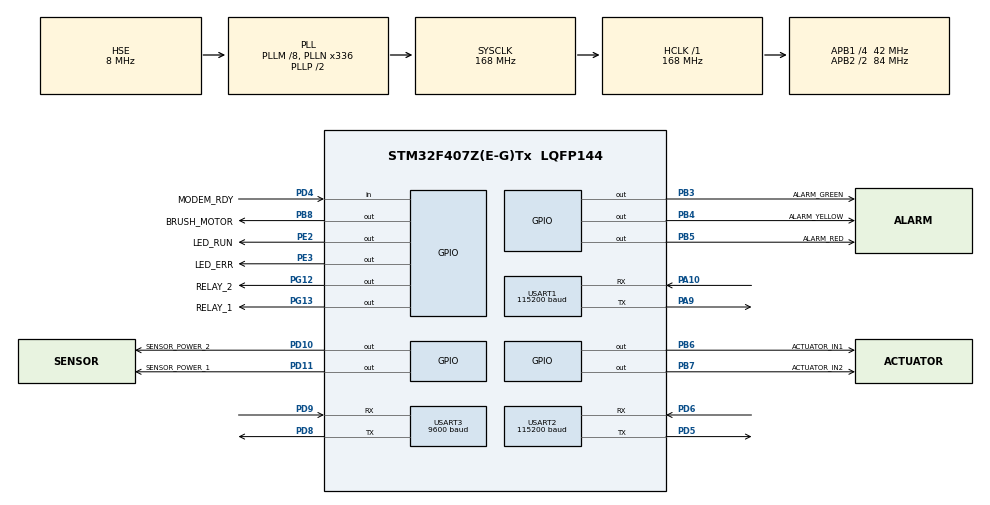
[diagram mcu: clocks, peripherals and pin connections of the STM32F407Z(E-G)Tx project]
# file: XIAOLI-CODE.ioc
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Mcu.Family=STM32F4
Mcu.Name=STM32F407Z(E-G)Tx
Mcu.Package=LQFP144
NVIC.PriorityGroup=NVIC_PRIORITYGROUP_4
NVIC.USART1_IRQn=true\:5\:0\:false\:false\:true\:true\:true
NVIC.USART2_IRQn=true\:5\:0\:false\:false\:true\:true\:true
NVIC.USART3_IRQn=true\:5\:0\:false\:false\:true\:true\:true
PA10.Mode=Asynchronous
PA10.Signal=USART1_RX
PA13.Mode=Serial_Wire
PA13.Signal=SYS_JTMS-SWDIO
PA14.Mode=Serial_Wire
PA14.Signal=SYS_JTCK-SWCLK
PA9.Mode=Asynchronous
PA9.Signal=USART1_TX
PB3.GPIO_Label=ALARM_GREEN
PB3.GPIO_ModeDefaultOutputPP=GPIO_MODE_OUTPUT_PP
PB3.GPIO_PuPd=GPIO_NOPULL
PB3.GPIO_Speed=GPIO_SPEED_FREQ_LOW
PB3.PinState=GPIO_PIN_SET
PB3.Signal=GPIO_Output
PB4.GPIO_Label=ALARM_YELLOW
PB4.GPIO_ModeDefaultOutputPP=GPIO_MODE_OUTPUT_PP
PB4.GPIO_PuPd=GPIO_NOPULL
PB4.GPIO_Speed=GPIO_SPEED_FREQ_LOW
PB4.PinState=GPIO_PIN_SET
PB4.Signal=GPIO_Output
PB5.GPIO_Label=ALARM_RED
PB5.GPIO_ModeDefaultOutputPP=GPIO_MODE_OUTPUT_PP
PB5.GPIO_PuPd=GPIO_NOPULL
PB5.GPIO_Speed=GPIO_SPEED_FREQ_LOW
PB5.PinState=GPIO_PIN_SET
PB5.Signal=GPIO_Output
PB6.GPIO_Label=ACTUATOR_IN1
PB6.GPIO_ModeDefaultOutputPP=GPIO_MODE_OUTPUT_PP
PB6.GPIO_PuPd=GPIO_NOPULL
PB6.GPIO_Speed=GPIO_SPEED_FREQ_LOW
PB6.PinState=GPIO_PIN_RESET
PB6.Signal=GPIO_Output
PB7.GPIO_Label=ACTUATOR_IN2
PB7.GPIO_ModeDefaultOutputPP=GPIO_MODE_OUTPUT_PP
PB7.GPIO_PuPd=GPIO_NOPULL
PB7.GPIO_Speed=GPIO_SPEED_FREQ_LOW
PB7.PinState=GPIO_PIN_RESET
PB7.Signal=GPIO_Output
PB8.GPIO_Label=BRUSH_MOTOR
PB8.GPIO_ModeDefaultOutputPP=GPIO_MODE_OUTPUT_PP
PB8.GPIO_PuPd=GPIO_NOPULL
PB8.GPIO_Speed=GPIO_SPEED_FREQ_LOW
PB8.PinState=GPIO_PIN_SET
PB8.Signal=GPIO_Output
PC14-OSC32_IN.Mode=LSE-External-Oscillator
PC14-OSC32_IN.Signal=RCC_OSC32_IN
PC15-OSC32_OUT.Mode=LSE-External-Oscillator
PC15-OSC32_OUT.Signal=RCC_OSC32_OUT
PD10.GPIO_Label=SENSOR_POWER_2
PD10.GPIO_ModeDefaultOutputPP=GPIO_MODE_OUTPUT_PP
PD10.GPIO_PuPd=GPIO_NOPULL
PD10.GPIO_Speed=GPIO_SPEED_FREQ_LOW
PD10.PinState=GPIO_PIN_SET
PD10.Signal=GPIO_Output
PD11.GPIO_Label=SENSOR_POWER_1
PD11.GPIO_ModeDefaultOutputPP=GPIO_MODE_OUTPUT_PP
PD11.GPIO_PuPd=GPIO_NOPULL
PD11.GPIO_Speed=GPIO_SPEED_FREQ_LOW
PD11.PinState=GPIO_PIN_SET
PD11.Signal=GPIO_Output
PD4.GPIO_Label=MODEM_RDY
PD4.GPIO_Mode=GPIO_MODE_INPUT
PD4.GPIO_PuPd=GPIO_NOPULL
PD4.Signal=GPIO_Input
PD5.Mode=Asynchronous
PD5.Signal=USART2_TX
PD6.Mode=Asynchronous
PD6.Signal=USART2_RX
PD8.Mode=Asynchronous
PD8.Signal=USART3_TX
PD9.Mode=Asynchronous
PD9.Signal=USART3_RX
PE2.GPIO_Label=LED_RUN
PE2.GPIO_ModeDefaultOutputPP=GPIO_MODE_OUTPUT_PP
PE2.GPIO_PuPd=GPIO_NOPULL
PE2.GPIO_Speed=GPIO_SPEED_FREQ_LOW
PE2.PinState=GPIO_PIN_SET
PE2.Signal=GPIO_Output
PE3.GPIO_Label=LED_ERR
PE3.GPIO_ModeDefaultOutputPP=GPIO_MODE_OUTPUT_PP
PE3.GPIO_PuPd=GPIO_NOPULL
PE3.GPIO_Speed=GPIO_SPEED_FREQ_LOW
PE3.PinState=GPIO_PIN_SET
PE3.Signal=GPIO_Output
PG12.GPIO_Label=RELAY_2
PG12.GPIO_ModeDefaultOutputPP=GPIO_MODE_OUTPUT_PP
PG12.GPIO_PuPd=GPIO_NOPULL
PG12.GPIO_Speed=GPIO_SPEED_FREQ_LOW
PG12.PinState=GPIO_PIN_SET
PG12.Signal=GPIO_Output
PG13.GPIO_Label=RELAY_1
PG13.GPIO_ModeDefaultOutputPP=GPIO_MODE_OUTPUT_PP
PG13.GPIO_PuPd=GPIO_NOPULL
PG13.GPIO_Speed=GPIO_SPEED_FREQ_LOW
PG13.PinState=GPIO_PIN_SET
PG13.Signal=GPIO_Output
PH0-OSC_IN.Mode=HSE-External-Oscillator
PH0-OSC_IN.Signal=RCC_OSC_IN
PH1-OSC_OUT.Mode=HSE-External-Oscillator
PH1-OSC_OUT.Signal=RCC_OSC_OUT
ProjectManager.HeapSize=0x200
ProjectManager.StackSize=0x1000
Xiaoli.ApplicationFlashSize=0x000E0000
Xiaoli.ConfigFlashBase=0x080E0000
Xiaoli.ConfigFlashSize=0x00020000
ProjectManager.TargetToolchain=MDK-ARM V5.32
RCC.48MHZClocksFreq_Value=48000000
RCC.AHBFreq_Value=168000000
RCC.APB1CLKDivider=RCC_HCLK_DIV4
RCC.APB1Freq_Value=42000000
RCC.APB1TimFreq_Value=84000000
RCC.APB2CLKDivider=RCC_HCLK_DIV2
RCC.APB2Freq_Value=84000000
RCC.APB2TimFreq_Value=168000000
RCC.CortexFreq_Value=168000000
RCC.HCLKFreq_Value=168000000
RCC.HSE_VALUE=8000000
RCC.HSI_VALUE=16000000
RCC.PLLM=8
RCC.PLLN=336
RCC.PLLQ=7
RCC.PLLSourceVirtual=RCC_PLLSOURCE_HSE
RCC.SYSCLKFreq_VALUE=168000000
RCC.SYSCLKSource=RCC_SYSCLKSOURCE_PLLCLK
RCC.VCOOutputFreq_Value=336000000
USART1.BaudRate=115200
USART1.Mode=MODE_TX_RX
USART1.OverSampling=UART_OVERSAMPLING_16
USART1.Parity=PARITY_NONE
USART1.StopBits=STOPBITS_1
USART1.VirtualMode=VM_ASYNC
USART1.WordLength=WORDLENGTH_8B
USART2.BaudRate=115200
USART2.Mode=MODE_TX_RX
USART2.OverSampling=UART_OVERSAMPLING_16
USART2.Parity=PARITY_NONE
USART2.StopBits=STOPBITS_1
USART2.VirtualMode=VM_ASYNC
USART2.WordLength=WORDLENGTH_8B
USART3.BaudRate=9600
USART3.Mode=MODE_TX_RX
USART3.OverSampling=UART_OVERSAMPLING_16
USART3.Parity=PARITY_NONE
USART3.StopBits=STOPBITS_1
USART3.VirtualMode=VM_ASYNC
USART3.WordLength=WORDLENGTH_8B
board=custom

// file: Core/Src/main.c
/* USER CODE BEGIN Header */
/**
  ******************************************************************************
  * @file           : main.c
  * @brief          : Main program body
  ******************************************************************************
  * @attention
  *
  * <h2><center>&copy; Copyright (c) 2026 STMicroelectronics.
  * All rights reserved.</center></h2>
  *
  * This software component is licensed by ST under BSD 3-Clause license,
  * the "License"; You may not use this file except in compliance with the
  * License. You may obtain a copy of the License at:
  *                        opensource.org/licenses/BSD-3-Clause
  *
  ******************************************************************************
  */
/* USER CODE END Header */
#include "main.h"
#include "usart.h"
#include "gpio.h"

/* USER CODE BEGIN Includes */
#include "application.h"

/* USER CODE END Includes */

void SystemClock_Config(void);

int main(void)
{

  /* MCU Configuration--------------------------------------------------------*/

  /* Reset of all peripherals, Initializes the Flash interface and the Systick. */
  HAL_Init();

  /* Configure the system clock */
  SystemClock_Config();

  /* Initialize all configured peripherals */
  MX_GPIO_Init();
  MX_USART1_UART_Init();
  MX_USART2_UART_Init();
  MX_USART3_UART_Init();
  /* USER CODE BEGIN 2 */

  Application_Init();

  /* USER CODE END 2 */

  /* Infinite loop */
  while (1)
  {

    /* USER CODE BEGIN 3 */
    Application_Task();
    HAL_Delay(1U);
  }
  /* USER CODE END 3 */
}

void SystemClock_Config(void)
{
  RCC_OscInitTypeDef RCC_OscInitStruct = {0};
  RCC_ClkInitTypeDef RCC_ClkInitStruct = {0};

  /** Configure the main internal regulator output voltage
  */
  __HAL_RCC_PWR_CLK_ENABLE();
  __HAL_PWR_VOLTAGESCALING_CONFIG(PWR_REGULATOR_VOLTAGE_SCALE1);
  /** Initializes the RCC Oscillators according to the specified parameters
  * in the RCC_OscInitTypeDef structure.
  */
  RCC_OscInitStruct.OscillatorType = RCC_OSCILLATORTYPE_HSE;
  RCC_OscInitStruct.HSEState = RCC_HSE_ON;
  RCC_OscInitStruct.PLL.PLLState = RCC_PLL_ON;
  RCC_OscInitStruct.PLL.PLLSource = RCC_PLLSOURCE_HSE;
  RCC_OscInitStruct.PLL.PLLM = 8;
  RCC_OscInitStruct.PLL.PLLN = 336;
  RCC_OscInitStruct.PLL.PLLP = RCC_PLLP_DIV2;
  RCC_OscInitStruct.PLL.PLLQ = 7;
  if (HAL_RCC_OscConfig(&RCC_OscInitStruct) != HAL_OK)
  {
    Error_Handler();
  }
  /** Initializes the CPU, AHB and APB buses clocks
  */
  RCC_ClkInitStruct.ClockType = RCC_CLOCKTYPE_HCLK|RCC_CLOCKTYPE_SYSCLK
                              |RCC_CLOCKTYPE_PCLK1|RCC_CLOCKTYPE_PCLK2;
  RCC_ClkInitStruct.SYSCLKSource = RCC_SYSCLKSOURCE_PLLCLK;
  RCC_ClkInitStruct.AHBCLKDivider = RCC_SYSCLK_DIV1;
  RCC_ClkInitStruct.APB1CLKDivider = RCC_HCLK_DIV4;
  RCC_ClkInitStruct.APB2CLKDivider = RCC_HCLK_DIV2;

  if (HAL_RCC_ClockConfig(&RCC_ClkInitStruct, FLASH_LATENCY_5) != HAL_OK)
  {
    Error_Handler();
  }
}

void Error_Handler(void)
{
  /* USER CODE BEGIN Error_Handler_Debug */
  /* 即使时钟或串口初始化失败，也先恢复全部输出为关闭状�?�并�? ERR�? */
  MX_GPIO_Init();
  HAL_GPIO_WritePin(LED_ERR_GPIO_Port, LED_ERR_Pin, GPIO_PIN_RESET);
  __disable_irq();
  while (1)
  {
  }
  /* USER CODE END Error_Handler_Debug */
}

/************************ (C) COPYRIGHT STMicroelectronics *****END OF FILE****/
